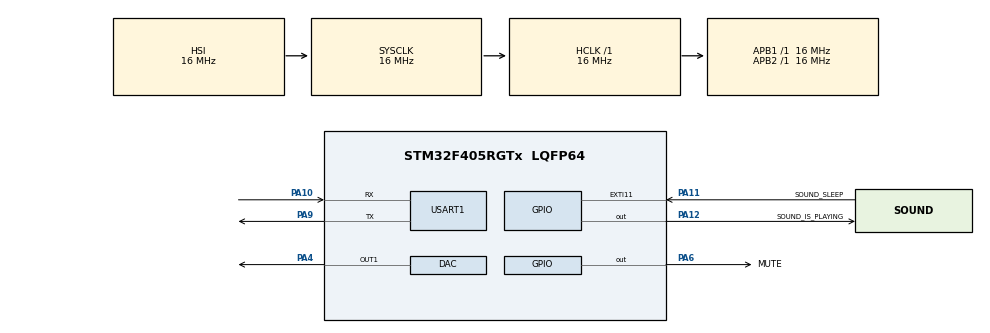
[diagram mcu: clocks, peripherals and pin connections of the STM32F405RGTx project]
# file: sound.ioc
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DAC.DAC_Trigger=DAC_TRIGGER_T6_TRGO
Dma.DAC1.0.Direction=DMA_MEMORY_TO_PERIPH
Dma.DAC1.0.FIFOMode=DMA_FIFOMODE_DISABLE
Dma.DAC1.0.Instance=DMA1_Stream5
Dma.DAC1.0.MemDataAlignment=DMA_MDATAALIGN_HALFWORD
Dma.DAC1.0.MemInc=DMA_MINC_ENABLE
Dma.DAC1.0.Mode=DMA_NORMAL
Dma.DAC1.0.PeriphDataAlignment=DMA_PDATAALIGN_HALFWORD
Dma.DAC1.0.PeriphInc=DMA_PINC_DISABLE
Dma.DAC1.0.Priority=DMA_PRIORITY_LOW
Dma.Request0=DAC1
Mcu.Family=STM32F4
Mcu.Name=STM32F405RGTx
Mcu.Package=LQFP64
NVIC.DMA1_Stream5_IRQn=true\:1\:0\:true\:false\:true\:false
NVIC.EXTI15_10_IRQn=true\:3\:0\:true\:false\:true\:true
NVIC.PriorityGroup=NVIC_PRIORITYGROUP_4
NVIC.USART1_IRQn=true\:2\:0\:true\:false\:true\:true
PA10.Mode=Asynchronous
PA10.Signal=USART1_RX
PA11.GPIO_Label=SOUND_SLEEP
PA11.Signal=GPXTI11
PA12.GPIO_Label=SOUND_IS_PLAYING
PA12.Signal=GPIO_Output
PA13.Mode=Serial_Wire
PA13.Signal=SYS_JTMS-SWDIO
PA14.Mode=Serial_Wire
PA14.Signal=SYS_JTCK-SWCLK
PA4.Signal=COMP_DAC1_group
PA6.GPIO_Label=MUTE
PA6.Signal=GPIO_Output
PA9.Mode=Asynchronous
PA9.Signal=USART1_TX
ProjectManager.HeapSize=0x200
ProjectManager.StackSize=0x400
ProjectManager.TargetToolchain=Makefile
RCC.AHBFreq_Value=16000000
RCC.APB1Freq_Value=16000000
RCC.APB2Freq_Value=16000000
RCC.CortexFreq_Value=16000000
RCC.HSE_VALUE=25000000
RCC.HSI_VALUE=16000000
RCC.LSE_VALUE=32768
RCC.SYSCLKFreq_VALUE=16000000
RCC.VCOOutputFreq_Value=192000000
SH.COMP_DAC1_group.0=DAC_OUT1,DAC_OUT1
TIM6.Period=999
TIM6.TIM_MasterOutputTrigger=TIM_TRGO_UPDATE
USART1.VirtualMode=VM_ASYNC
VP_TIM6_VS_ClockSourceINT.Mode=Enable_Timer
board=sound

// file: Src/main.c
/**
 ******************************************************************************
 * @file           : main.c
 * @brief          : Main program body
 ******************************************************************************
 ** This notice applies to any and all portions of this file
 * that are not between comment pairs USER CODE BEGIN and
 * USER CODE END. Other portions of this file, whether
 * inserted by the user or by software development tools
 * are owned by their respective copyright owners.
 *
 * COPYRIGHT(c) 2018 STMicroelectronics
 *
 * Redistribution and use in source and binary forms, with or without modification,
 * are permitted provided that the following conditions are met:
 *   1. Redistributions of source code must retain the above copyright notice,
 *      this list of conditions and the following disclaimer.
 *   2. Redistributions in binary form must reproduce the above copyright notice,
 *      this list of conditions and the following disclaimer in the documentation
 *      and/or other materials provided with the distribution.
 *   3. Neither the name of STMicroelectronics nor the names of its contributors
 *      may be used to endorse or promote products derived from this software
 *      without specific prior written permission.
 *
 * THIS SOFTWARE IS PROVIDED BY THE COPYRIGHT HOLDERS AND CONTRIBUTORS "AS IS"
 * AND ANY EXPRESS OR IMPLIED WARRANTIES, INCLUDING, BUT NOT LIMITED TO, THE
 * IMPLIED WARRANTIES OF MERCHANTABILITY AND FITNESS FOR A PARTICULAR PURPOSE ARE
 * DISCLAIMED. IN NO EVENT SHALL THE COPYRIGHT HOLDER OR CONTRIBUTORS BE LIABLE
 * FOR ANY DIRECT, INDIRECT, INCIDENTAL, SPECIAL, EXEMPLARY, OR CONSEQUENTIAL
 * DAMAGES (INCLUDING, BUT NOT LIMITED TO, PROCUREMENT OF SUBSTITUTE GOODS OR
 * SERVICES; LOSS OF USE, DATA, OR PROFITS; OR BUSINESS INTERRUPTION) HOWEVER
 * CAUSED AND ON ANY THEORY OF LIABILITY, WHETHER IN CONTRACT, STRICT LIABILITY,
 * OR TORT (INCLUDING NEGLIGENCE OR OTHERWISE) ARISING IN ANY WAY OUT OF THE USE
 * OF THIS SOFTWARE, EVEN IF ADVISED OF THE POSSIBILITY OF SUCH DAMAGE.
 *
 ******************************************************************************
 */
#include "main.h"
#include "stm32f4xx_hal.h"

/* USER CODE BEGIN Includes */
#include "sound.hpp"
#include "sound_player.hpp"
/* USER CODE END Includes */

DAC_HandleTypeDef hdac;
DMA_HandleTypeDef hdma_dac1;

TIM_HandleTypeDef htim6;

UART_HandleTypeDef huart1;

/* USER CODE BEGIN PV */
/* Private variables ---------------------------------------------------------*/

/* USER CODE END PV */

void SystemClock_Config(void);
static void MX_GPIO_Init(void);
static void MX_DMA_Init(void);
static void MX_DAC_Init(void);
static void MX_USART1_UART_Init(void);
static void MX_TIM6_Init(void);

/* USER CODE BEGIN PFP */
/* Private function prototypes -----------------------------------------------*/

/* USER CODE END PFP */

int main(void)
{

    /* MCU Configuration----------------------------------------------------------*/

    /* Reset of all peripherals, Initializes the Flash interface and the Systick. */
    HAL_Init();

    /* Configure the system clock */
    SystemClock_Config();

    /* Initialize all configured peripherals */
    MX_GPIO_Init();
    MX_DMA_Init();
    MX_DAC_Init();
    MX_USART1_UART_Init();
    MX_TIM6_Init();
    /* USER CODE BEGIN 2 */

    sound_player = new SoundPlayer(&huart1, &hdac, &hdma_dac1, &htim6, DAC_CHANNEL_1);

    /* USER CODE END 2 */

    /* Infinite loop */
    /* USER CODE BEGIN WHILE */
    while (1)
    {
        // sound_player.set_pin_is_playing(sound_player.is_sound_playing());

        /* USER CODE END WHILE */

    }
} /* main */

void SystemClock_Config(void)
{
    RCC_OscInitTypeDef RCC_OscInitStruct;
    RCC_ClkInitTypeDef RCC_ClkInitStruct;

    /**Configure the main internal regulator output voltage
     */
    __HAL_RCC_PWR_CLK_ENABLE();

    __HAL_PWR_VOLTAGESCALING_CONFIG(PWR_REGULATOR_VOLTAGE_SCALE1);

    /**Initializes the CPU, AHB and APB busses clocks
     */
    RCC_OscInitStruct.OscillatorType      = RCC_OSCILLATORTYPE_HSI;
    RCC_OscInitStruct.HSIState            = RCC_HSI_ON;
    RCC_OscInitStruct.HSICalibrationValue = 16;
    RCC_OscInitStruct.PLL.PLLState        = RCC_PLL_NONE;
    if (HAL_RCC_OscConfig(&RCC_OscInitStruct) != HAL_OK)
    {
        _Error_Handler(__FILE__, __LINE__);
    }

    /**Initializes the CPU, AHB and APB busses clocks
     */
    RCC_ClkInitStruct.ClockType = RCC_CLOCKTYPE_HCLK | RCC_CLOCKTYPE_SYSCLK
      | RCC_CLOCKTYPE_PCLK1 | RCC_CLOCKTYPE_PCLK2;
    RCC_ClkInitStruct.SYSCLKSource   = RCC_SYSCLKSOURCE_HSI;
    RCC_ClkInitStruct.AHBCLKDivider  = RCC_SYSCLK_DIV1;
    RCC_ClkInitStruct.APB1CLKDivider = RCC_HCLK_DIV1;
    RCC_ClkInitStruct.APB2CLKDivider = RCC_HCLK_DIV1;

    if (HAL_RCC_ClockConfig(&RCC_ClkInitStruct, FLASH_LATENCY_0) != HAL_OK)
    {
        _Error_Handler(__FILE__, __LINE__);
    }

    /**Configure the Systick interrupt time
     */
    HAL_SYSTICK_Config(HAL_RCC_GetHCLKFreq() / 1000);

    /**Configure the Systick
     */
    HAL_SYSTICK_CLKSourceConfig(SYSTICK_CLKSOURCE_HCLK);

    /* SysTick_IRQn interrupt configuration */
    HAL_NVIC_SetPriority(SysTick_IRQn, 0, 0);
} /* SystemClock_Config */

/* DAC init function */
static void MX_DAC_Init(void)
{
    DAC_ChannelConfTypeDef sConfig;

    /**DAC Initialization
     */
    hdac.Instance = DAC;
    if (HAL_DAC_Init(&hdac) != HAL_OK)
    {
        _Error_Handler(__FILE__, __LINE__);
    }

    /**DAC channel OUT1 config
     */
    sConfig.DAC_Trigger      = DAC_TRIGGER_T6_TRGO;
    sConfig.DAC_OutputBuffer = DAC_OUTPUTBUFFER_ENABLE;
    if (HAL_DAC_ConfigChannel(&hdac, &sConfig, DAC_CHANNEL_1) != HAL_OK)
    {
        _Error_Handler(__FILE__, __LINE__);
    }
}

/* TIM6 init function */
static void MX_TIM6_Init(void)
{
    TIM_MasterConfigTypeDef sMasterConfig;

    htim6.Instance         = TIM6;
    htim6.Init.Prescaler   = 0;
    htim6.Init.CounterMode = TIM_COUNTERMODE_UP;
    htim6.Init.Period      = 999;
    if (HAL_TIM_Base_Init(&htim6) != HAL_OK)
    {
        _Error_Handler(__FILE__, __LINE__);
    }

    sMasterConfig.MasterOutputTrigger = TIM_TRGO_UPDATE;
    sMasterConfig.MasterSlaveMode     = TIM_MASTERSLAVEMODE_DISABLE;
    if (HAL_TIMEx_MasterConfigSynchronization(&htim6, &sMasterConfig) != HAL_OK)
    {
        _Error_Handler(__FILE__, __LINE__);
    }
}

/* USART1 init function */
static void MX_USART1_UART_Init(void)
{
    huart1.Instance          = USART1;
    huart1.Init.BaudRate     = 115200;
    huart1.Init.WordLength   = UART_WORDLENGTH_8B;
    huart1.Init.StopBits     = UART_STOPBITS_1;
    huart1.Init.Parity       = UART_PARITY_NONE;
    huart1.Init.Mode         = UART_MODE_TX_RX;
    huart1.Init.HwFlowCtl    = UART_HWCONTROL_NONE;
    huart1.Init.OverSampling = UART_OVERSAMPLING_16;
    if (HAL_UART_Init(&huart1) != HAL_OK)
    {
        _Error_Handler(__FILE__, __LINE__);
    }
}

static void MX_DMA_Init(void)
{
    /* DMA controller clock enable */
    __HAL_RCC_DMA1_CLK_ENABLE();

    /* DMA interrupt init */
    /* DMA1_Stream5_IRQn interrupt configuration */
    HAL_NVIC_SetPriority(DMA1_Stream5_IRQn, 1, 0);
    HAL_NVIC_EnableIRQ(DMA1_Stream5_IRQn);
}

/** Configure pins as
 * Analog
 * Input
 * Output
 * EVENT_OUT
 * EXTI
 */
static void MX_GPIO_Init(void)
{
    GPIO_InitTypeDef GPIO_InitStruct;

    /* GPIO Ports Clock Enable */
    __HAL_RCC_GPIOA_CLK_ENABLE();

    /*Configure GPIO pin Output Level */
    HAL_GPIO_WritePin(GPIOA, MUTE_Pin | SOUND_IS_PLAYING_Pin, GPIO_PIN_RESET);

    /*Configure GPIO pins : MUTE_Pin SOUND_IS_PLAYING_Pin */
    GPIO_InitStruct.Pin   = MUTE_Pin | SOUND_IS_PLAYING_Pin;
    GPIO_InitStruct.Mode  = GPIO_MODE_OUTPUT_PP;
    GPIO_InitStruct.Pull  = GPIO_NOPULL;
    GPIO_InitStruct.Speed = GPIO_SPEED_FREQ_LOW;
    HAL_GPIO_Init(GPIOA, &GPIO_InitStruct);

    /*Configure GPIO pin : SOUND_SLEEP_Pin */
    GPIO_InitStruct.Pin  = SOUND_SLEEP_Pin;
    GPIO_InitStruct.Mode = GPIO_MODE_IT_RISING;
    GPIO_InitStruct.Pull = GPIO_NOPULL;
    HAL_GPIO_Init(SOUND_SLEEP_GPIO_Port, &GPIO_InitStruct);

    /* EXTI interrupt init*/
    HAL_NVIC_SetPriority(EXTI15_10_IRQn, 3, 0);
    HAL_NVIC_EnableIRQ(EXTI15_10_IRQn);
}

void _Error_Handler(char *file, int line)
{
    /* USER CODE BEGIN Error_Handler_Debug */
    /* User can add his own implementation to report the HAL error return state */
    while (1)
    { }
    /* USER CODE END Error_Handler_Debug */
}

#ifdef  USE_FULL_ASSERT

/**
 * @brief  Reports the name of the source file and the source line number
 *         where the assert_param error has occurred.
 * @param  file: pointer to the source file name
 * @param  line: assert_param error line source number
 * @retval None
 */
void assert_failed(uint8_t *file, uint32_t line)
{
    /* USER CODE BEGIN 6 */

    /* User can add his own implementation to report the file name and line number,
     * tex: printf("Wrong parameters value: file %s on line %d\r\n", file, line) */
    /* USER CODE END 6 */
}

#endif /* USE_FULL_ASSERT */

/************************ (C) COPYRIGHT STMicroelectronics *****END OF FILE****/
